# FM33A0XXER register map
File version: 1.0
CPU: SC000, little endian, no MPU, no FPU, 3 interrupt priority bits
Registers are 32-bit, read-write, reset 0x0 unless marked. A register's access mark holds for its fields unless they carry their own. Offsets are from the block's base; [hi:lo] are bit positions; {n}, {i} and the like mark numbered series.

## ET1 — ET1 module information
Base 0x40013090
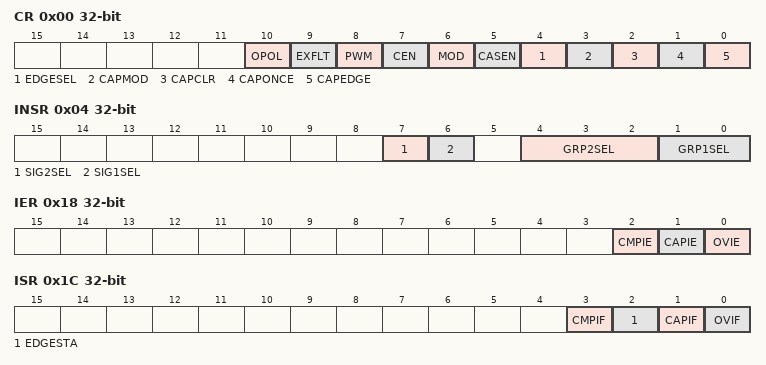
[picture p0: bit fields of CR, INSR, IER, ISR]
0x00 CR — ET1 Control Register
  [10] OPOL — OPOL field description
  [9] EXFLT — EXFLT field description
  [8] PWM — PWM field description
  [7] CEN — CEN field description
  [6] MOD — MOD field description
  [5] CASEN — CASEN field description
  [4] EDGESEL — EDGESEL field description
  [3] CAPMOD — CAPMOD field description
  [2] CAPCLR — CAPCLR field description
  [1] CAPONCE — CAPONCE field description
  [0] CAPEDGE — CAPEDGE field description
0x04 INSR — ET1 Input Select Register
  [7] SIG2SEL — SIG2SEL field description
  [6] SIG1SEL — SIG1SEL field description
  [4:2] GRP2SEL — GRP2SEL field description
  [1:0] GRP1SEL — GRP1SEL field description
0x08 PSCR1 — ET1 Prescaler Register1
  [7:0] PRESCALE1 — PRESCALE1 field description
0x0C PSCR2 — ET1 Prescaler Register2
  [7:0] PRESCALE2 — PRESCALE2 field description
0x10 IVR — ET1 Initial Value Register
  [15:0] INITVALUE — INITVALUE field description
0x14 CMPR — ET1 Compare Register
  [15:0] CMP — CMP field description
0x18 IER — ET1 Interrupt Enable Register
  [2] CMPIE — CMPIE field description
  [1] CAPIE — CAPIE field description
  [0] OVIE — OVIE field description
0x1C ISR — ET1 Interrupt Status Register
  [3] CMPIF — CMPIF field description
  [2] EDGESTA — EDGESTA field description
  [1] CAPIF — CAPIF field description
  [0] OVIF — OVIF field description

## ET2 — ET2 module information
Base 0x400130B0
Registers as ET1 (with ET1 read as ET2).

## ET3 — ET3 module information
Base 0x400130D0
Registers as ET1 (with ET1 read as ET3).

## ET4 — ET4 module information
Base 0x400130F0
Registers as ET1 (with ET1 read as ET4).

## BSTIM — BSTIM module information
Base 0x40016000
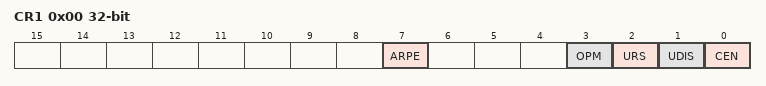
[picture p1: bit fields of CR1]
0x00 CR1 — BSTIM Control Register1
  [7] ARPE — ARPE field description
  [3] OPM — OPM field description
  [2] URS — URS field description
  [1] UDIS — UDIS field description
  [0] CEN — CEN field description
0x04 CR2 — BSTIM Control Register2
  [6:4] MMS — MMS field description
0x0C IER — BSTIM Interrupt Enable Register
  [0] UIE — UIE field description
0x10 ISR — BSTIM Interrupt Status Register
  [0] UIF — UIF field description
0x14 EGR — BSTIM Event Generation Register
  [0] UG wo — UG field description
0x24 CNTR — BSTIM Counter Register
  [31:0] CNT — CNT field description
0x28 PSCR — BSTIM Prescaler Register
  [31:0] PSC — PSC field description
0x2C ARR — BSTIM Auto-Reload Register
  [31:0] ARR — ARR field description

## LPTIM — LPTIM module information
Base 0x40013400
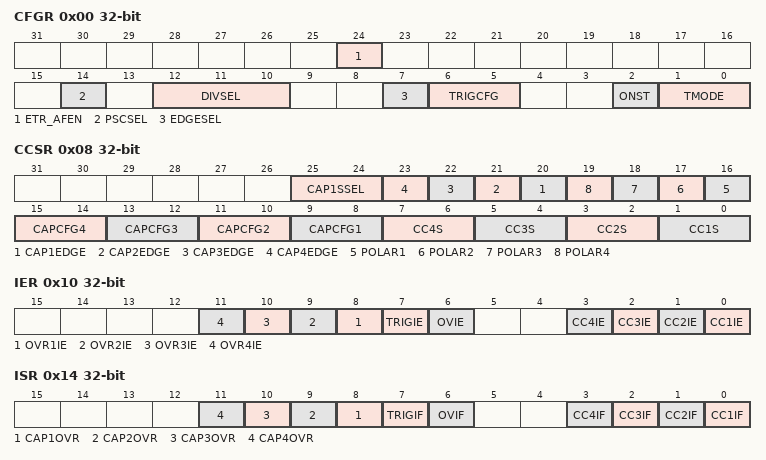
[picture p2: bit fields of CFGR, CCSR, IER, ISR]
0x00 CFGR — LPTIM Config Register
  [24] ETR_AFEN — ETR_AFEN field description
  [14] PSCSEL — PSCSEL field description
  [12:10] DIVSEL — DIVSEL field description
  [7] EDGESEL — EDGESEL field description
  [6:5] TRIGCFG — TRIGCFG field description
  [2] ONST — ONST field description
  [1:0] TMODE — TMODE field description
0x04 CNTR — LPTIM Counter Register
  [31:0] CNT32 ro — CNT32 field description
0x08 CCSR — LPTIM Capture/Compare Control and Status Register
  [25:24] CAP1SSEL — CAP1SSEL field description
  [n+19] CAP{n}EDGE (n=1..4) — CAP{n}EDGE field description
  [n+15] POLAR{n} (n=1..4) — POLAR{n} field description
  [2n+7:2n+6] CAPCFG{n} (n=1..4) — CAPCFG{n} field description
  [2n-1:2n-2] CC{n}S (n=1..4) — CC{n}S field description
0x0C ARR — LPTIM Auto-Reload Register
  [31:0] ARR — ARR field description
0x10 IER — LPTIM Interrupt Enable Register
  [n+7] OVR{n}IE (n=1..4) — OVR{n}IE field description
  [7] TRIGIE — TRIGIE field description
  [6] OVIE — OVIE field description
  [n-1] CC{n}IE (n=1..4) — CC{n}IE field description
0x14 ISR — LPTIM Interrupt Status Register
  [n+7] CAP{n}OVR (n=1..4) — CAP{n}OVR field description
  [7] TRIGIF — TRIGIF field description
  [6] OVIF — OVIF field description
  [n-1] CC{n}IF (n=1..4) — CC{n}IF field description
0x18 CR — LPTIM Control Register
  [0] EN — EN field description
{0x1C+4i} CCR{i} (i=1..4) — LPTIM Capture/Compare Register{i}
  [31:0] CCR{i} — CCR{i} field description
